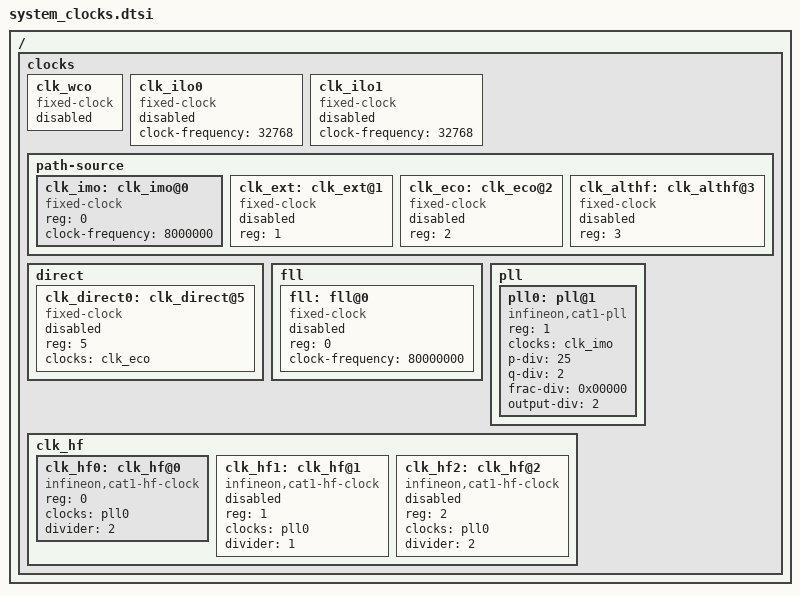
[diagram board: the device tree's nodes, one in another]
/*
 * Copyright (c) 2025 Infineon Technologies AG,
 * or an affiliate of Infineon Technologies AG.
 *
 * SPDX-License-Identifier: Apache-2.0
 */
#define DIV_8_BIT    00
#define DIV_16_BIT    01
#define DIV_16_5_BIT    02
#define DIV_24_5_BIT    03

#include <dt-bindings/clock/ifx_clock_source_def.h>
 / {
    clocks {
        clk_wco: clk_wco{
            #clock-cells = <0>;
            compatible = "fixed-clock";
            status = "disabled";
        };

        clk_ilo0: clk_ilo0 {
            #clock-cells = <0>;
            compatible = "fixed-clock";
            clock-frequency = <32768>;
            status = "disabled";
        };

        clk_ilo1: clk_ilo1 {
            #clock-cells = <0>;
            compatible = "fixed-clock";
            clock-frequency = <32768>;
            status = "disabled";
        };

        path-source {
            #address-cells = <1>;
            #size-cells = <0>;

            /* imo */
            clk_imo: clk_imo@0 {
                #clock-cells = <0>;
                compatible = "fixed-clock";
                reg = <0>;
                clock-frequency = <8000000>;
                status = "okay";
            };

            clk_ext: clk_ext@1 {
                #clock-cells = <0>;
                compatible = "fixed-clock";
                reg = <1>;
                status = "disabled";
            };

            clk_eco: clk_eco@2 {
                #clock-cells = <0>;
                compatible = "fixed-clock";
                reg = <2>;
                status = "disabled";
            };

            clk_althf: clk_althf@3 {
                #clock-cells = <0>;
                compatible = "fixed-clock";
                reg = <3>;
                status = "disabled";
            };
        };

        direct {
            #address-cells = <1>;
            #size-cells = <0>;
            clk_direct0: clk_direct@5 {
                #clock-cells = <0>;
                compatible = "fixed-clock";
                reg = <5>;
                clocks = <&clk_eco>;
                status = "disabled";
            };
        };


        fll {
            #address-cells = <1>;
            #size-cells = <0>;

            /* fll */
            fll: fll@0 {
                #clock-cells = <0>;
                reg = <0>;
                compatible = "fixed-clock";
                clock-frequency = <80000000>;
                status = "disabled";
            };
        };

        pll {
            #address-cells = <1>;
            #size-cells = <0>;

            pll0: pll@1 {
                #clock-cells = <0>;
                compatible = "infineon,cat1-pll";
                reg = <1>;
                clocks = <&clk_imo>;
                p-div = <25>;
                q-div = <2>;
                frac-div = <0x00000>;
                output-div = <2>;
                status = "okay";
            };
        };

        clk_hf {
            #address-cells = <1>;
            #size-cells = <0>;

            clk_hf0: clk_hf@0 {
                #clock-cells = <0>;
                compatible = "infineon,cat1-hf-clock";
                reg = <0>;
                clocks = <&pll0>;
                divider = <2>;
                status = "okay";
            };

            clk_hf1: clk_hf@1 {
                #clock-cells = <0>;
                compatible = "infineon,cat1-hf-clock";
                reg = <1>;
                clocks = <&pll0>;
                divider = <1>;
                status = "disabled";
            };

            clk_hf2: clk_hf@2 {
                #clock-cells = <0>;
                compatible = "infineon,cat1-hf-clock";
                reg = <2>;
                clocks = <&pll0>;
                divider = <2>;
                status = "disabled";
            };
        };
    };
};
